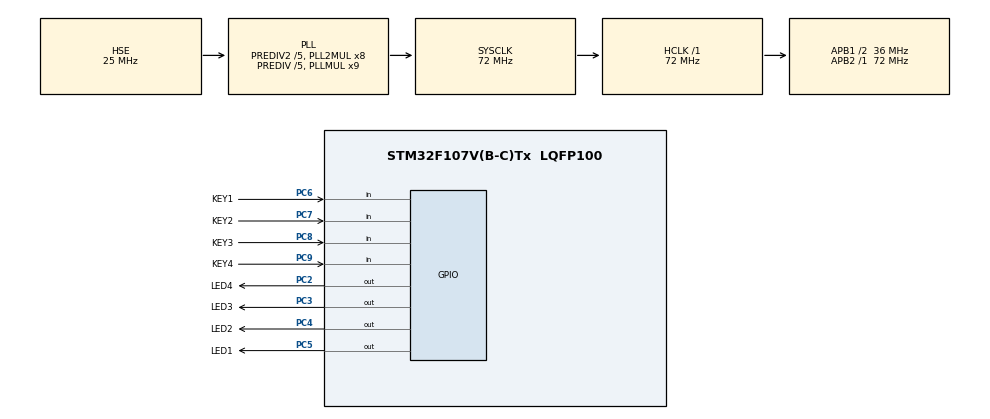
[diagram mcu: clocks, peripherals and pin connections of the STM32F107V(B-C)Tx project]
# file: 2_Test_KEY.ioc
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Mcu.Family=STM32F1
Mcu.Name=STM32F107V(B-C)Tx
Mcu.Package=LQFP100
NVIC.PriorityGroup=NVIC_PRIORITYGROUP_4
OSC_IN.Mode=HSE-External-Oscillator
OSC_IN.Signal=RCC_OSC_IN
OSC_OUT.Mode=HSE-External-Oscillator
OSC_OUT.Signal=RCC_OSC_OUT
PA13.Mode=Serial_Wire
PA13.Signal=SYS_JTMS-SWDIO
PA14.Mode=Serial_Wire
PA14.Signal=SYS_JTCK-SWCLK
PC2.GPIO_Label=LED4
PC2.Signal=GPIO_Output
PC3.GPIO_Label=LED3
PC3.Signal=GPIO_Output
PC4.GPIO_Label=LED2
PC4.Signal=GPIO_Output
PC5.GPIO_Label=LED1
PC5.PinState=GPIO_PIN_RESET
PC5.Signal=GPIO_Output
PC6.GPIO_Label=KEY1
PC6.Signal=GPIO_Input
PC7.GPIO_Label=KEY2
PC7.Signal=GPIO_Input
PC8.GPIO_Label=KEY3
PC8.Signal=GPIO_Input
PC9.GPIO_Label=KEY4
PC9.Signal=GPIO_Input
ProjectManager.HeapSize=0x200
ProjectManager.StackSize=0x400
ProjectManager.TargetToolchain=MDK-ARM V5.27
RCC.AHBFreq_Value=72000000
RCC.APB1CLKDivider=RCC_HCLK_DIV2
RCC.APB1Freq_Value=36000000
RCC.APB1TimFreq_Value=72000000
RCC.APB2Freq_Value=72000000
RCC.APB2TimFreq_Value=72000000
RCC.HCLKFreq_Value=72000000
RCC.HSEDivPLL=RCC_HSE_PREDIV_DIV5
RCC.HSE_VALUE=25000000
RCC.PLLMUL=RCC_PLL_MUL9
RCC.PLLSourceVirtual=RCC_PLLSOURCE_HSE
RCC.Prediv1Source=RCC_PREDIV1_SOURCE_PLL2
RCC.Prediv2=RCC_HSE_PREDIV2_DIV5
RCC.SYSCLKFreq_VALUE=72000000
RCC.SYSCLKSource=RCC_SYSCLKSOURCE_PLLCLK
RCC.USBFreq_Value=48000000
board=custom

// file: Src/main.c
/* USER CODE BEGIN Header */
//           ****************************************************
//          **   Processor      : STM32F107VCT6                   **
//         ***   Frequency      : 8MHz ExtClock 72MHZ CPU Clock   ***
//        ****   AUTHOR         : Mahdi Dadashi                   ****
//       *****   STM32CubeMX    : V5.40                           *****
//      ******   STM32CubeF1    : V1.8.0                          ******
//       *****   Compiler       : KEIL uVision V5.26              *****
//        ****   Instagram      : instagram.com/mahdidadashi65/   ****
//         ***   Telegram       : t.me/mahdidadashi65/            ***
//          **   Github         : github.com/mahdidadashi65/      **
//           ****************************************************
//.-''-._.-''-._.-''-._.-''-._.-''-._.-''-._.-''-._.-''-._.-''-._.-''-._.-''-._
//.-''-._.-''-._.-''                                 ''-._.-''-._.-''-._.-''-._
//.-''-._.-''-._.-''      www.mahdidadashi.ir        ''-._.-''-._.-''-._.-''-._
//.-''-._.-''-._.-''                                 ''-._.-''-._.-''-._.-''-._
//.-''-._.-''-._.-''-._.-''-._.-''-._.-''-._.-''-._.-''-._.-''-._.-''-._.-''-._
/* USER CODE END Header */

#include "main.h"

/* USER CODE BEGIN Includes */
//#include "..\MyApp/MyApp.h"
#include "MyApp.h"
/* USER CODE END Includes */

void SystemClock_Config(void);
static void MX_GPIO_Init(void);

int main(void)
{

  /* MCU Configuration--------------------------------------------------------*/

  /* Reset of all peripherals, Initializes the Flash interface and the Systick. */
  HAL_Init();

  /* Configure the system clock */
  SystemClock_Config();

  /* Initialize all configured peripherals */
  MX_GPIO_Init();
  /* USER CODE BEGIN 2 */

	MyApp();

  /* USER CODE END 2 */

  /* Infinite loop */
  while (1)
  {

  }
}

void SystemClock_Config(void)
{
  RCC_OscInitTypeDef RCC_OscInitStruct = {0};
  RCC_ClkInitTypeDef RCC_ClkInitStruct = {0};

  /** Initializes the CPU, AHB and APB busses clocks
  */
  RCC_OscInitStruct.OscillatorType = RCC_OSCILLATORTYPE_HSE;
  RCC_OscInitStruct.HSEState = RCC_HSE_ON;
  RCC_OscInitStruct.HSEPredivValue = RCC_HSE_PREDIV_DIV5;
  RCC_OscInitStruct.HSIState = RCC_HSI_ON;
  RCC_OscInitStruct.Prediv1Source = RCC_PREDIV1_SOURCE_PLL2;
  RCC_OscInitStruct.PLL.PLLState = RCC_PLL_ON;
  RCC_OscInitStruct.PLL.PLLSource = RCC_PLLSOURCE_HSE;
  RCC_OscInitStruct.PLL.PLLMUL = RCC_PLL_MUL9;
  RCC_OscInitStruct.PLL2.PLL2State = RCC_PLL2_ON;
  RCC_OscInitStruct.PLL2.PLL2MUL = RCC_PLL2_MUL8;
  RCC_OscInitStruct.PLL2.HSEPrediv2Value = RCC_HSE_PREDIV2_DIV5;
  if (HAL_RCC_OscConfig(&RCC_OscInitStruct) != HAL_OK)
  {
    Error_Handler();
  }
  /** Initializes the CPU, AHB and APB busses clocks
  */
  RCC_ClkInitStruct.ClockType = RCC_CLOCKTYPE_HCLK|RCC_CLOCKTYPE_SYSCLK
                              |RCC_CLOCKTYPE_PCLK1|RCC_CLOCKTYPE_PCLK2;
  RCC_ClkInitStruct.SYSCLKSource = RCC_SYSCLKSOURCE_PLLCLK;
  RCC_ClkInitStruct.AHBCLKDivider = RCC_SYSCLK_DIV1;
  RCC_ClkInitStruct.APB1CLKDivider = RCC_HCLK_DIV2;
  RCC_ClkInitStruct.APB2CLKDivider = RCC_HCLK_DIV1;

  if (HAL_RCC_ClockConfig(&RCC_ClkInitStruct, FLASH_LATENCY_2) != HAL_OK)
  {
    Error_Handler();
  }
  /** Configure the Systick interrupt time
  */
  __HAL_RCC_PLLI2S_ENABLE();
}

static void MX_GPIO_Init(void)
{
  GPIO_InitTypeDef GPIO_InitStruct = {0};

  /* GPIO Ports Clock Enable */
  __HAL_RCC_GPIOC_CLK_ENABLE();
  __HAL_RCC_GPIOA_CLK_ENABLE();

  /*Configure GPIO pin Output Level */
  HAL_GPIO_WritePin(GPIOC, LED4_Pin|LED3_Pin|LED2_Pin|LED1_Pin, GPIO_PIN_RESET);

  /*Configure GPIO pins : LED4_Pin LED3_Pin LED2_Pin LED1_Pin */
  GPIO_InitStruct.Pin = LED4_Pin|LED3_Pin|LED2_Pin|LED1_Pin;
  GPIO_InitStruct.Mode = GPIO_MODE_OUTPUT_PP;
  GPIO_InitStruct.Pull = GPIO_NOPULL;
  GPIO_InitStruct.Speed = GPIO_SPEED_FREQ_LOW;
  HAL_GPIO_Init(GPIOC, &GPIO_InitStruct);

  /*Configure GPIO pins : KEY1_Pin KEY2_Pin KEY3_Pin KEY4_Pin */
  GPIO_InitStruct.Pin = KEY1_Pin|KEY2_Pin|KEY3_Pin|KEY4_Pin;
  GPIO_InitStruct.Mode = GPIO_MODE_INPUT;
  GPIO_InitStruct.Pull = GPIO_NOPULL;
  HAL_GPIO_Init(GPIOC, &GPIO_InitStruct);

}

void Error_Handler(void)
{
}

/************************ (C) COPYRIGHT STMicroelectronics *****END OF FILE****/
